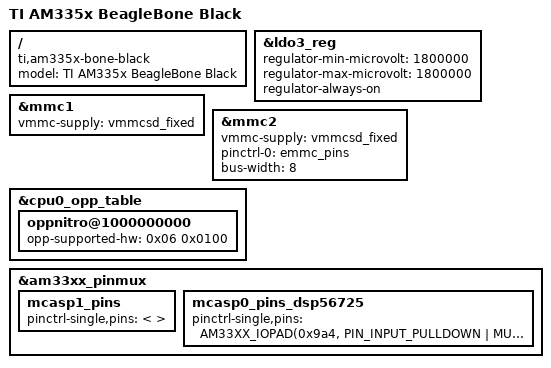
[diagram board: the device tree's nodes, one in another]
/*
 * Copyright (C) 2012 Texas Instruments Incorporated - http://www.ti.com/
 *
 * This program is free software; you can redistribute it and/or modify
 * it under the terms of the GNU General Public License version 2 as
 * published by the Free Software Foundation.
 */
/dts-v1/;

#include "am33xx.dtsi"
#include "am335x-bone-common.dtsi"
/* #include "am33xx-overlay-edma-fix.dtsi" */
#include <dt-bindings/display/tda998x.h>
/* #include "am335x-bone-jtag.dtsi" */

/* pruss: pick one: */

/*
 * /etc/modprobe.d/pruss-blacklist.conf
 *
 * blacklist uio_pruss
 */

/* #include "am33xx-pruss-rproc.dtsi" */

/*
 * /etc/modprobe.d/pruss-blacklist.conf
 *
 * blacklist pruss
 * blacklist pruss_intc
 * blacklist pru-rproc
 */

#include "am33xx-pruss-uio.dtsi"

/ {
	model = "TI AM335x BeagleBone Black";
	compatible = "ti,am335x-bone-black", "ti,am335x-bone", "ti,am33xx";
};

&ldo3_reg {
	regulator-min-microvolt = <1800000>;
	regulator-max-microvolt = <1800000>;
	regulator-always-on;
};

&mmc1 {
	vmmc-supply = <&vmmcsd_fixed>;
};

&mmc2 {
	vmmc-supply = <&vmmcsd_fixed>;
	pinctrl-names = "default";
	pinctrl-0 = <&emmc_pins>;
	bus-width = <8>;
	status = "okay";
};

&cpu0_opp_table {
	/*
	 * All PG 2.0 silicon may not support 1GHz but some of the early
	 * BeagleBone Blacks have PG 2.0 silicon which is guaranteed
	 * to support 1GHz OPP so enable it for PG 2.0 on this board.
	 */
	oppnitro@1000000000 {
		opp-supported-hw = <0x06 0x0100>;
	};
};


&am33xx_pinmux {
	mcasp1_pins: mcasp1_pins {
		pinctrl-single,pins = <
			//0x190 (PIN_OUTPUT_PULLDOWN | MUX_MODE0)	/* mcasp0_aclkx */
			//0x194 (PIN_OUTPUT_PULLDOWN | MUX_MODE0)	/* mcasp0_fsx*/
			//0x198 (PIN_OUTPUT_PULLDOWN | MUX_MODE0)	/* mcasp0_axr0 */

		>;
	};
	/* dsp56725 cape */
	mcasp0_pins_dsp56725: mcasp0_pins_dsp56725 {
		pinctrl-single,pins = <
			AM33XX_IOPAD(0x9a4, PIN_INPUT_PULLDOWN | MUX_MODE0 )  /* mcasp0_fsr,             MODE0 | INPUT P9_27   GPIO3_19 */
			AM33XX_IOPAD(0x878, PIN_INPUT_PULLDOWN | MUX_MODE6 )  /* mcasp0_aclkr_mux3,      MODE6 | INPUT P9_12   gpio1_28 */
              
			AM33XX_IOPAD(0x998, PIN_INPUT | MUX_MODE0)  /* mcasp0_axr0,            MODE0 | INPUT P9_30   GPIO3_16 */
			////AM33XX_IOPAD(0x98a, PIN_INPUT | MUX_MODE0)  /* mcasp0_axr1,            MODE0 | INPUT P9_41B   GPIO3_20*/
			////AM33XX_IOPAD(0x99c, PIN_INPUT | MUX_MODE2)  /* mcasp0_axr2             MODE2 | INPUT P9_28   GPIO3_17  */
			//AM33XX_IOPAD(0x9ac, PIN_INPUT_PULLUP | MUX_MODE2)  /* mcasp0_axr3,            MODE2 | INPUT P9_25   GPIO3_21*/
			                       /*OFFSET DIR|MODE */
	
	       //0x194 0x20  /* mcasp0_fsx,    	MODE0 | INPUT */
	       //0x190 0x20  /* mcasp0_aclkx   	MODE0 | INPUT */
	       //0x198 0x20  /* mcasp0_axr0,       MODE0 | INPUT */
	       //0x19c 0x22  /* mcasp0_axr2  	MODE2 | INPUT */
               //0x1a4 0x22 /* mcasp0_axr3, MODE2 | INPUT */    

		>;
	};
};
 
//&mcasp1 {
//		#sound-dai-cells = <0>;
//		pinctrl-names = "default";
//		pinctrl-0 = <&mcasp1_pins>;
//		status = "okay";
//		op-mode = <0>;          /* MCASP_IIS_MODE */
//		tdm-slots = <2>;
		
//		serial-dir = <  /* 0: INACTIVE, 1: TX, 2: RX */
//			1 0 0 0
//		>;
//		tx-num-evt = <32>;
//		rx-num-evt = <32>;
//};
 
/// {
// 
//	pcm5102a: pcm5102a {
//		#sound-dai-cells = <0>;
//		compatible = "ti,pcm5102a";
//	};
 
//	sound {
//		compatible = "ti,pcm5102a-evm-audio";
//		ti,model = "TI PCM5102A";
//		ti,audio-codec = <&pcm5102a>;
//		ti,mcasp-controller = <&mcasp1>;
//		ti,codec-clock-rate = <24000000>;
//	};
 
//};

#include "am335x-bone-dsp56725.dtsi"
